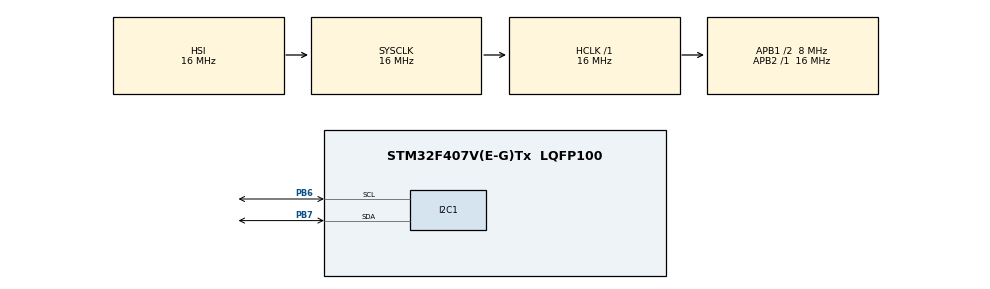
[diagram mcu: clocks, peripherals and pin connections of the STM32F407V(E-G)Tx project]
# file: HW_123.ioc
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Mcu.Family=STM32F4
Mcu.Name=STM32F407V(E-G)Tx
Mcu.Package=LQFP100
NVIC.PriorityGroup=NVIC_PRIORITYGROUP_4
PB6.Mode=I2C
PB6.Signal=I2C1_SCL
PB7.Mode=I2C
PB7.Signal=I2C1_SDA
ProjectManager.HeapSize=0x200
ProjectManager.StackSize=0x400
ProjectManager.TargetToolchain=STM32CubeIDE
RCC.48MHZClocksFreq_Value=50000000
RCC.AHBFreq_Value=16000000
RCC.APB1CLKDivider=RCC_HCLK_DIV2
RCC.APB1Freq_Value=8000000
RCC.APB1TimFreq_Value=16000000
RCC.APB2Freq_Value=16000000
RCC.APB2TimFreq_Value=16000000
RCC.CortexFreq_Value=16000000
RCC.HCLKFreq_Value=16000000
RCC.HSE_VALUE=8000000
RCC.HSI_VALUE=16000000
RCC.LSE_VALUE=32768
RCC.PLLM=4
RCC.PLLN=50
RCC.SYSCLKFreq_VALUE=16000000
RCC.VCOOutputFreq_Value=200000000
board=custom

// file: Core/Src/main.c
/* USER CODE BEGIN Header */
/**
 ******************************************************************************
 * @file           : main.c
 * @brief          : Main program body
 ******************************************************************************
 * @attention
 *
 * Copyright (c) 2026 STMicroelectronics.
 * All rights reserved.
 *
 * This software is licensed under terms that can be found in the LICENSE file
 * in the root directory of this software component.
 * If no LICENSE file comes with this software, it is provided AS-IS.
 *
 ******************************************************************************
 */
/* USER CODE END Header */
#include "main.h"

/* USER CODE BEGIN PD */

#define MPU6050_WRITE_ADDR		0xD0
#define MPU6050_READ_ADDR   	0xD1

/* USER CODE END PD */

I2C_HandleTypeDef hi2c1;

/* USER CODE BEGIN PV */

typedef struct {
	int16_t accel_x;
	int16_t accel_y;
	int16_t accel_z;
} Acceleration_t;

Acceleration_t accel_g;

typedef struct {
	int16_t gyro_x;
	int16_t gyro_y;
	int16_t gyro_z;
} Gyroscope_t;

Gyroscope_t gyro_g;

typedef struct {
	Acceleration_t accel;
	Gyroscope_t gyro;
} MPU6050_t;

MPU6050_t angle_info_g;

/* USER CODE END PV */

void SystemClock_Config(void);
static void MX_GPIO_Init(void);
static void MX_I2C1_Init(void);

/* USER CODE BEGIN 0 */

Acceleration_t Get_Acceleration(void);
Gyroscope_t Get_Gyroscope(void);
MPU6050_t Get_Angle_Info(void);
uint8_t MPU6050_Init(uint8_t wake, uint8_t accel_mode, uint8_t gyro_mode,
		uint8_t dlpf_mode);
uint8_t MPU6050_Init_Default(void);

Acceleration_t Get_Acceleration(void) {

	uint8_t buffer[6];

	Acceleration_t accel;

	HAL_I2C_Mem_Read(&hi2c1, MPU6050_READ_ADDR, 0x3B, I2C_MEMADD_SIZE_8BIT,
			buffer, 6, 100);

	accel.accel_x = (int16_t) (buffer[0] << 8) | buffer[1];
	accel.accel_y = (int16_t) (buffer[2] << 8) | buffer[3];
	accel.accel_z = (int16_t) (buffer[4] << 8) | buffer[5];

	return accel;
}

Gyroscope_t Get_Gyroscope(void) {

	uint8_t buffer[6];

	Gyroscope_t gyro;

	HAL_I2C_Mem_Read(&hi2c1, MPU6050_READ_ADDR, 0x43, I2C_MEMADD_SIZE_8BIT,
			buffer, 6, 100);

	gyro.gyro_x = (int16_t) (buffer[0] << 8) | buffer[1];
	gyro.gyro_y = (int16_t) (buffer[2] << 8) | buffer[3];
	gyro.gyro_z = (int16_t) (buffer[4] << 8) | buffer[5];

	return gyro;
}

MPU6050_t Get_Angle_Info(void) { //Infolar ekle

	uint8_t buffer[14];

	Acceleration_t accel;
	Gyroscope_t gyro;
	MPU6050_t angleInfo;

	HAL_I2C_Mem_Read(&hi2c1, MPU6050_READ_ADDR, 0x3B, I2C_MEMADD_SIZE_8BIT,
			buffer, 14, 100);

	accel.accel_x = (int16_t) (buffer[0] << 8) | buffer[1];
	accel.accel_y = (int16_t) (buffer[2] << 8) | buffer[3];
	accel.accel_z = (int16_t) (buffer[4] << 8) | buffer[5];

	gyro.gyro_x = (int16_t) (buffer[8] << 8) | buffer[9];
	gyro.gyro_y = (int16_t) (buffer[10] << 8) | buffer[11];
	gyro.gyro_z = (int16_t) (buffer[12] << 8) | buffer[13];

	angleInfo.accel = accel;
	angleInfo.gyro = gyro;

	return angleInfo;

}

uint8_t MPU6050_Init(uint8_t wake, uint8_t accel_mode, uint8_t gyro_mode,
		uint8_t dlpf_mode) {

	// Device check (WHO_AM_I register)
	uint8_t chip_id;

	HAL_I2C_Mem_Read(&hi2c1, MPU6050_WRITE_ADDR, 0x75, I2C_MEMADD_SIZE_8BIT,
			&chip_id, 1, 100);

	if (chip_id != 0x68) {
		return 0;
	}

	HAL_I2C_Mem_Write(&hi2c1, MPU6050_WRITE_ADDR, 0x6B, I2C_MEMADD_SIZE_8BIT,
			&wake, 1, 100);

	HAL_I2C_Mem_Write(&hi2c1, MPU6050_WRITE_ADDR, 0x1C, I2C_MEMADD_SIZE_8BIT,
			&accel_mode, 1, 100);

	HAL_I2C_Mem_Write(&hi2c1, MPU6050_WRITE_ADDR, 0x1B, I2C_MEMADD_SIZE_8BIT,
			&gyro_mode, 1, 100);

	HAL_I2C_Mem_Write(&hi2c1, MPU6050_WRITE_ADDR, 0x1A, I2C_MEMADD_SIZE_8BIT,
			&dlpf_mode, 1, 100);

	return 1;
}

uint8_t MPU6050_Init_Default(void) {

	// Wake: 0x00, Accel (+-2g): 0x00, Gyro (+-250dps): 0x00, DLPF (~42Hz): 0x03
	return MPU6050_Init(0x00, 0x00, 0x00, 0x03);
}

/* USER CODE END 0 */

int main(void) {

	/* MCU Configuration--------------------------------------------------------*/

	/* Reset of all peripherals, Initializes the Flash interface and the Systick. */
	HAL_Init();

	/* Configure the system clock */
	SystemClock_Config();

	/* Initialize all configured peripherals */
	MX_GPIO_Init();
	MX_I2C1_Init();
	/* USER CODE BEGIN 2 */

	MPU6050_Init_Default();

	/* USER CODE END 2 */

	/* Infinite loop */
	while (1) {

		/* USER CODE BEGIN 3 */

		angle_info_g = Get_Angle_Info();
		HAL_Delay(10);
	}
	/* USER CODE END 3 */
}

void SystemClock_Config(void) {
	RCC_OscInitTypeDef RCC_OscInitStruct = { 0 };
	RCC_ClkInitTypeDef RCC_ClkInitStruct = { 0 };

	/** Configure the main internal regulator output voltage
	 */
	__HAL_RCC_PWR_CLK_ENABLE();
	__HAL_PWR_VOLTAGESCALING_CONFIG(PWR_REGULATOR_VOLTAGE_SCALE1);

	/** Initializes the RCC Oscillators according to the specified parameters
	 * in the RCC_OscInitTypeDef structure.
	 */
	RCC_OscInitStruct.OscillatorType = RCC_OSCILLATORTYPE_HSI;
	RCC_OscInitStruct.HSIState = RCC_HSI_ON;
	RCC_OscInitStruct.HSICalibrationValue = RCC_HSICALIBRATION_DEFAULT;
	RCC_OscInitStruct.PLL.PLLState = RCC_PLL_NONE;
	if (HAL_RCC_OscConfig(&RCC_OscInitStruct) != HAL_OK) {
		Error_Handler();
	}

	/** Initializes the CPU, AHB and APB buses clocks
	 */
	RCC_ClkInitStruct.ClockType = RCC_CLOCKTYPE_HCLK | RCC_CLOCKTYPE_SYSCLK
			| RCC_CLOCKTYPE_PCLK1 | RCC_CLOCKTYPE_PCLK2;
	RCC_ClkInitStruct.SYSCLKSource = RCC_SYSCLKSOURCE_HSI;
	RCC_ClkInitStruct.AHBCLKDivider = RCC_SYSCLK_DIV1;
	RCC_ClkInitStruct.APB1CLKDivider = RCC_HCLK_DIV2;
	RCC_ClkInitStruct.APB2CLKDivider = RCC_HCLK_DIV1;

	if (HAL_RCC_ClockConfig(&RCC_ClkInitStruct, FLASH_LATENCY_0) != HAL_OK) {
		Error_Handler();
	}
}

static void MX_I2C1_Init(void) {

	hi2c1.Instance = I2C1;
	hi2c1.Init.ClockSpeed = 100000;
	hi2c1.Init.DutyCycle = I2C_DUTYCYCLE_2;
	hi2c1.Init.OwnAddress1 = 0;
	hi2c1.Init.AddressingMode = I2C_ADDRESSINGMODE_7BIT;
	hi2c1.Init.DualAddressMode = I2C_DUALADDRESS_DISABLE;
	hi2c1.Init.OwnAddress2 = 0;
	hi2c1.Init.GeneralCallMode = I2C_GENERALCALL_DISABLE;
	hi2c1.Init.NoStretchMode = I2C_NOSTRETCH_DISABLE;
	if (HAL_I2C_Init(&hi2c1) != HAL_OK) {
		Error_Handler();
	}

}

static void MX_GPIO_Init(void) {

	/* GPIO Ports Clock Enable */
	__HAL_RCC_GPIOB_CLK_ENABLE();

}

void Error_Handler(void) {
	__disable_irq();
	while (1) {
	}
}
